# CY8C5888LTI_LP097 register map
File version: 0.1
CY8C58LP
Registers are 8-bit, read-write, no defined reset value unless marked. A register's access mark holds for its fields unless they carry their own. Offsets are from the block's base; lines under a group give offsets from that group; [hi:lo] are bit positions; {n}, {i} and the like mark numbered series; 'fields as' and 'values as' point back to an identical list; <NAME> marks a mode.

## Memory map
0x00000000 elbowPWM
0x00000000 baseRotationPWM
0x00000000 elbowPWM
0x00000000 wristRollPWM
0x00000000 baseElevationPWM
0x00000000 wristPitchPWM
0x00000000 UART

## elbowPWM
Base 0x00000000
0x40006524 elbowPWM_COMPARE_Reg 16-bit — UDB.D0 - Assigned Compare Value
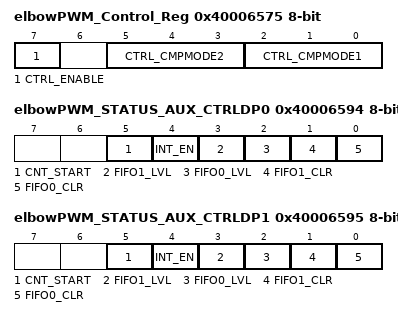
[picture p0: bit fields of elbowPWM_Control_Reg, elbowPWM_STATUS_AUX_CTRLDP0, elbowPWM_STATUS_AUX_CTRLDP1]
0x40006575 elbowPWM_Control_Reg — UDB Control Register - Assigned Control Register Value
  [7] CTRL_ENABLE — Enable the PWM
  [5:3] CTRL_CMPMODE2 — Compare mode 2
  [2:0] CTRL_CMPMODE1 — Compare mode 1
0x40006594 elbowPWM_STATUS_AUX_CTRLDP0 — UDB Auxilliary Control Register
  [5] CNT_START — FIFO0 clear
    0=E_CNT_START0 (Disable counter); 1=E_CNT_START1 (Enable counter)
  [4] INT_EN
    0=E_INT_EN0 (Interrupt disabled); 1=E_INT_EN1 (Interrupt enabled)
  [3] FIFO1_LVL — FIFO level
    0=E_FIFO_LVL_0 (FIFO LVL: input mode: FIFO not full; output mode: FIFO not empty); 1=E_FIFO_LVL_1 (FIFO LVL: input mode: FIFO at least 1/2 empty; output mode: FIFO at least 1/2 full)
  [2] FIFO0_LVL — FIFO level
    values as FIFO1_LVL
  [1] FIFO1_CLR — FIFO1 clear
    0=E_FIFO_CLR_0 (Normal FIFO operation); 1=E_FIFO_CLR_1 (Clear FIFO state)
  [0] FIFO0_CLR — FIFO0 clear
    values as FIFO1_CLR
0x40006595 elbowPWM_STATUS_AUX_CTRLDP1 — UDB Auxilliary Control Register
  fields as elbowPWM_STATUS_AUX_CTRLDP0

## baseRotationPWM
Base 0x00000000
0x40006526 baseRotationPWM_COMPARE_Reg 16-bit — UDB.D0 - Assigned Compare Value
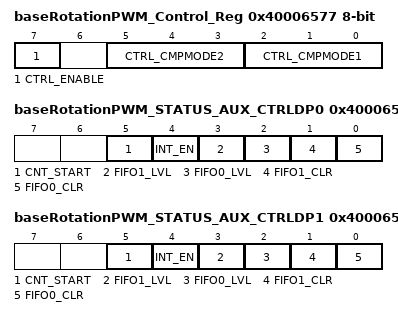
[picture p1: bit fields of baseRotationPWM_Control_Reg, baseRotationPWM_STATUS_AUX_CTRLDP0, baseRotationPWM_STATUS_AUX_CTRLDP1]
0x40006577 baseRotationPWM_Control_Reg — UDB Control Register - Assigned Control Register Value
  [7] CTRL_ENABLE — Enable the PWM
  [5:3] CTRL_CMPMODE2 — Compare mode 2
  [2:0] CTRL_CMPMODE1 — Compare mode 1
0x40006596 baseRotationPWM_STATUS_AUX_CTRLDP0 — UDB Auxilliary Control Register
  fields as elbowPWM.elbowPWM_STATUS_AUX_CTRLDP0
0x40006597 baseRotationPWM_STATUS_AUX_CTRLDP1 — UDB Auxilliary Control Register
  fields as elbowPWM.elbowPWM_STATUS_AUX_CTRLDP0

## elbowPWM
Base 0x00000000
Registers as elbowPWM (with elbowPWM read as elbowPWM).

## wristRollPWM
Base 0x00000000
0x40006426 wristRollPWM_COMPARE_Reg 16-bit — UDB.D0 - Assigned Compare Value
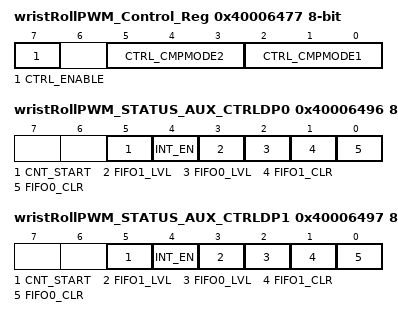
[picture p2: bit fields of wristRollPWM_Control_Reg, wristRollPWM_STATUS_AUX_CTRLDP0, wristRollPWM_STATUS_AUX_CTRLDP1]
0x40006477 wristRollPWM_Control_Reg — UDB Control Register - Assigned Control Register Value
  [7] CTRL_ENABLE — Enable the PWM
  [5:3] CTRL_CMPMODE2 — Compare mode 2
  [2:0] CTRL_CMPMODE1 — Compare mode 1
0x40006496 wristRollPWM_STATUS_AUX_CTRLDP0 — UDB Auxilliary Control Register
  fields as elbowPWM.elbowPWM_STATUS_AUX_CTRLDP0
0x40006497 wristRollPWM_STATUS_AUX_CTRLDP1 — UDB Auxilliary Control Register
  fields as elbowPWM.elbowPWM_STATUS_AUX_CTRLDP0

## baseElevationPWM
Base 0x00000000
0x40006424 baseElevationPWM_COMPARE_Reg 16-bit — UDB.D0 - Assigned Compare Value
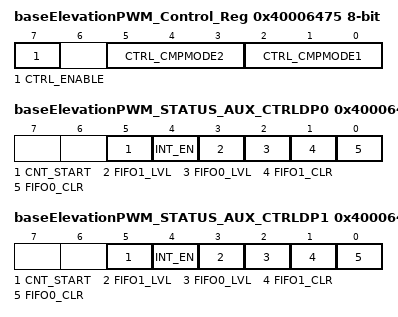
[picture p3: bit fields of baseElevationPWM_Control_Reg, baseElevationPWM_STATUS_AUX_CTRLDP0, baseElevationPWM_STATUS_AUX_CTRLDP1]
0x40006475 baseElevationPWM_Control_Reg — UDB Control Register - Assigned Control Register Value
  [7] CTRL_ENABLE — Enable the PWM
  [5:3] CTRL_CMPMODE2 — Compare mode 2
  [2:0] CTRL_CMPMODE1 — Compare mode 1
0x40006494 baseElevationPWM_STATUS_AUX_CTRLDP0 — UDB Auxilliary Control Register
  fields as elbowPWM.elbowPWM_STATUS_AUX_CTRLDP0
0x40006495 baseElevationPWM_STATUS_AUX_CTRLDP1 — UDB Auxilliary Control Register
  fields as elbowPWM.elbowPWM_STATUS_AUX_CTRLDP0

## wristPitchPWM
Base 0x00000000
0x40006528 wristPitchPWM_COMPARE_Reg 16-bit — UDB.D0 - Assigned Compare Value
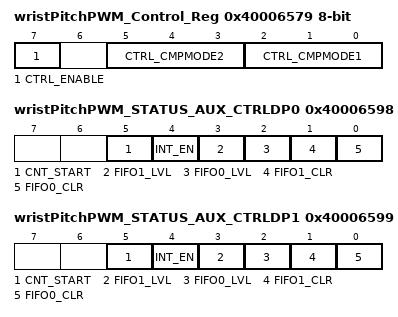
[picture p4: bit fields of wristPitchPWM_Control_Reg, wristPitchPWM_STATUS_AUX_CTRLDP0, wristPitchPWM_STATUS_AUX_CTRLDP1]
0x40006579 wristPitchPWM_Control_Reg — UDB Control Register - Assigned Control Register Value
  [7] CTRL_ENABLE — Enable the PWM
  [5:3] CTRL_CMPMODE2 — Compare mode 2
  [2:0] CTRL_CMPMODE1 — Compare mode 1
0x40006598 wristPitchPWM_STATUS_AUX_CTRLDP0 — UDB Auxilliary Control Register
  fields as elbowPWM.elbowPWM_STATUS_AUX_CTRLDP0
0x40006599 wristPitchPWM_STATUS_AUX_CTRLDP1 — UDB Auxilliary Control Register
  fields as elbowPWM.elbowPWM_STATUS_AUX_CTRLDP0

## UART
Base 0x00000000
0x4000642A RX_UART_RX_ADDRESS1 — RX Address1 Register
0x4000643A RX_UART_RX_ADDRESS2 — RX Address2 Register
0x40006448 TX_UART_TX_DATA — TX Data Register
0x4000644A RX_UART_RX_DATA — RX Data Register
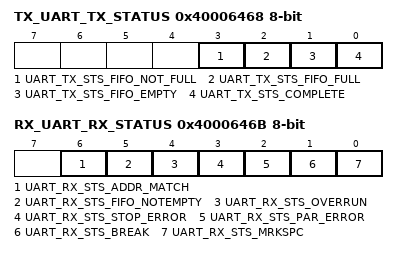
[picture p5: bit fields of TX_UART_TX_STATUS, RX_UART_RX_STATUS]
0x40006468 TX_UART_TX_STATUS — TX status register
  [3] UART_TX_STS_FIFO_NOT_FULL ro, [2] UART_TX_STS_FIFO_FULL ro, [1] UART_TX_STS_FIFO_EMPTY ro, [0] UART_TX_STS_COMPLETE ro
0x4000646B RX_UART_RX_STATUS — RX status register
  [6] UART_RX_STS_ADDR_MATCH ro, [5] UART_RX_STS_FIFO_NOTEMPTY ro, [4] UART_RX_STS_OVERRUN ro, [3] UART_RX_STS_STOP_ERROR ro, [2] UART_RX_STS_PAR_ERROR ro, [1] UART_RX_STS_BREAK ro, [0] UART_RX_STS_MRKSPC ro
